# SAMA7G54D2G device description
Architecture: CORTEX-A7; Family: SAMA; Series: SAMA7G
Registers are 32-bit, read-write, reset 0x0 unless marked. A register's access mark holds for its fields unless they carry their own. Offsets are from the block's base; [hi:lo] are bit positions; {n}, {i} and the like mark numbered series; 'fields as' and 'values as' point back to an identical list.

## PMC — Power Management Controller
Instances: PMC 0xE0018000
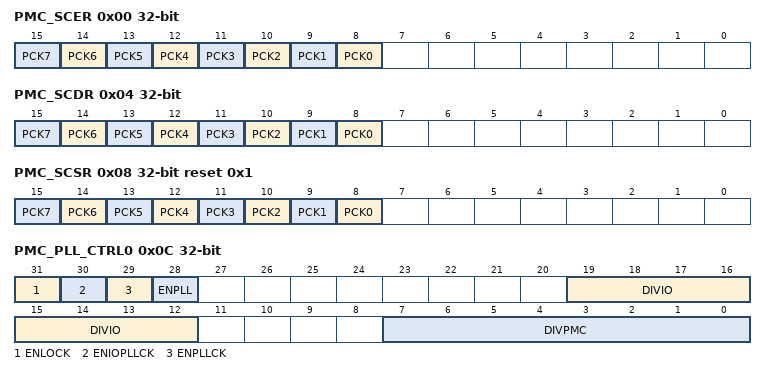
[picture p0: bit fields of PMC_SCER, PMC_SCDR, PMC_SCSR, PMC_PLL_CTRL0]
0x00 PMC_SCER wo reset not defined — System Clock Enable Register
  [all] fields
    0=No effect; 1=Enables the corresponding Programmable Clock output
  [n+8] PCK{n} (n=0..7) — Programmable Clock {n} Output Enable
0x04 PMC_SCDR wo reset not defined (atomic clear of PMC_SCSR) — System Clock Disable Register
  [all] fields
    0=No effect; 1=Disables the corresponding Programmable Clock output
  [n+8] PCK{n} (n=0..7) — Programmable Clock {n} Output Disable
0x08 PMC_SCSR ro reset 0x1 — System Clock Status Register
  [all] fields
    0=The corresponding Programmable Clock output is disabled; 1=The corresponding Programmable Clock output is enabled
  [n+8] PCK{n} (n=0..7) — Programmable Clock {n} Output Status
0x0C PMC_PLL_CTRL0 — PLL Control Register 0
  [31] ENLOCK — Enable PLL Lock
    0=The lock signal sent by the PLL is ignored. The PLL is considered as locked once the start-up time defined by PMC_PLL_UPDT.STUPTIM has elapsed.; 1=The PLL is considered as locked once the start-up time defined by PMC_PLL_UPDT.STUPTIM has elapsed and the lock signal sent by the PLL has risen
  [30] ENIOPLLCK — Enable PLL Clock for IO
    0=The clock generated by the PLL is not send to the IO; 1=The clock generated by the PLL is sent to the IO
  [29] ENPLLCK — Enable PLL Clock for PMC
    0=The clock generated by the PLL is not send to the IP_Acronym; 1=The clock generated by the PLL is sent to the IP_Acronym
  [28] ENPLL — Enable PLL
    0=The PLL is off; 1=The PLL is on
  [19:12] DIVIO — Divider for PAD
  [7:0] DIVPMC — Divider for PMC
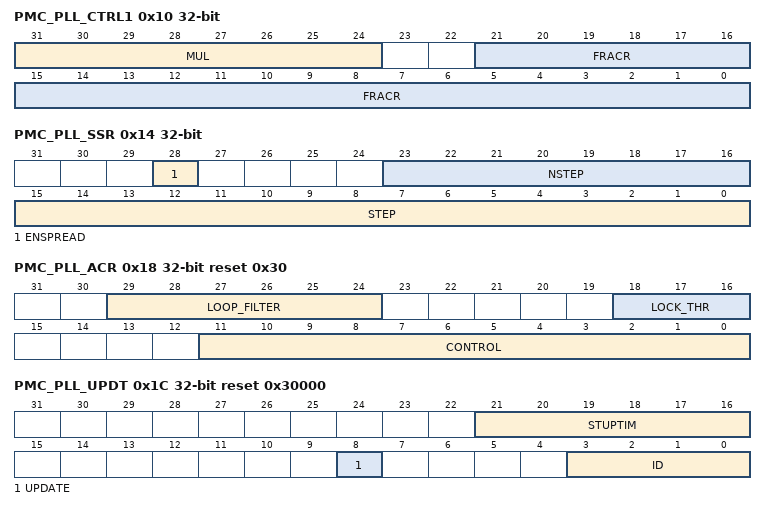
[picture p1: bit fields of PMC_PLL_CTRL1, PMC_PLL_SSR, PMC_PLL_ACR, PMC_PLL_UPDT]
0x10 PMC_PLL_CTRL1 — PLL Control Register 1
  [31:24] MUL — Multiplier Factor Value
  [21:0] FRACR — Fractional Loop Divider Setting
0x14 PMC_PLL_SSR — PLL Spread Spectrum Register
  [28] ENSPREAD — Spread Spectrum Enable
    0=The spread spectrum is not applied to the PLL; 1=The spread spectrum is applied to the PLL
  [23:16] NSTEP — Spread Spectrum Number of Steps
  [15:0] STEP — Spread Spectrum Step Size
0x18 PMC_PLL_ACR reset 0x30 — PLL Analog Control Register
  [29:24] LOOP_FILTER — LOOP Filter Selection
  [18:16] LOCK_THR — PLL Lock Threshold Value Selection
  [11:0] CONTROL — PLL CONTROL Value Selection
0x1C PMC_PLL_UPDT reset 0x30000 — PLL Update Register
  [21:16] STUPTIM — Start-up Time
    0=Only the lock of the PLL is considered to know the lock status of the PLL. If the lock of the PLL is not enabled, the lock never rises.
  [8] UPDATE — PLL Setting Update (write-only)
    0=No effect; 1=The PLL configuration written in PMC_PLL_CTRL0 and PMC_PLL_CTRL1 are applied to the PLL defined by the last ID written in the PMC_PLL_CTRL0 register
  [3:0] ID — PLL ID
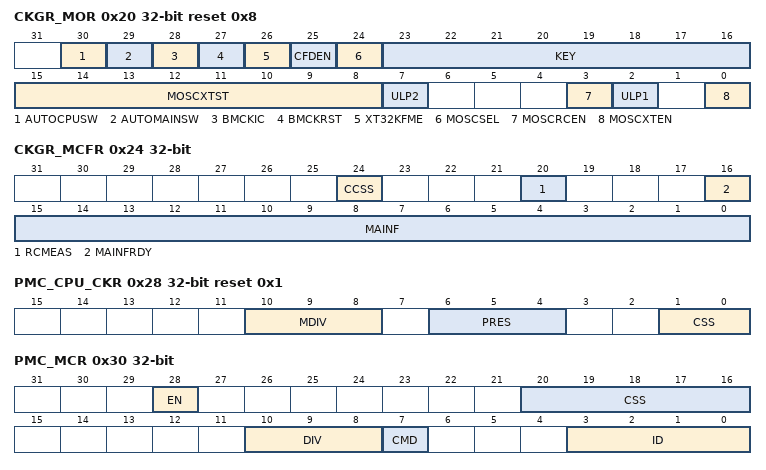
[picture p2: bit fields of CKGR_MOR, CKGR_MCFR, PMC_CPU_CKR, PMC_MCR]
0x20 CKGR_MOR reset 0x8 — Main Oscillator Register
  [30] AUTOCPUSW — Automatic Processor Clock Source Switching
    0=A main crystal oscillator failure detection has no effect on the processor clock source selection; 1=If a main crystal oscillator failure is detected, the processor clock source selection automatically switches to the main clock
  [29] AUTOMAINSW — Automatic Main Clock Source Switching
    0=A main crystal oscillator failure detection has no effect on the main clock source selection; 1=If a main crystal oscillator failure is detected, the main clock source selection automatically switches to the main RC
  [28] BMCKIC — Bad MCK0 Clock Interrupt
    0=An MCK0 clock failure has no effect on the Interrupt Controller; 1=An MCK0 clock failure detection sends an interrupt signal to the Interrupt Controller
  [27] BMCKRST — Bad MCK0 Clock Reset Enable
    0=An MCK0 clock failure detection cannot reset the system; 1=An MCK0 clock failure detection can reset the system if the reset controller is configured accordingly
  [26] XT32KFME — 32.768 kHz Crystal Oscillator Frequency Monitoring Enable
    0=The 32.768 kHz crystal oscillator frequency monitoring is disabled; 1=The 32.768 kHz crystal oscillator frequency monitoring is enabled
  [25] CFDEN — Clock Failure Detector Enable
    0=The clock failure detector is disabled; 1=The clock failure detector is enabled
  [24] MOSCSEL — Main Clock Oscillator Selection
    0=RC (The main RC oscillator is selected.); 1=XT (The main crystal oscillator is selected.)
  [23:16] KEY — Write Access Password
    55=PASSWD (Writing any other value in this field aborts the write operation. Always reads as 0.)
  [15:8] MOSCXTST — Main Crystal Oscillator Start-up Time
  [7] ULP2 — ULP Mode 2 Command (write-only)
    0=No effect; 1=Enables the device to enter ULP mode 2. ULP mode 2 is entered when the processor WFE instruction is executed.
  [3] MOSCRCEN — Main RC Oscillator Enable
    0=The main RC oscillator is disabled; 1=The main RC oscillator is enabled
  [2] ULP1 — ULP Mode 1 Command (write-only)
    0=No effect; 1=Puts the device in ULP mode 1
  [0] MOSCXTEN — Main Crystal Oscillator Enable
    0=The main crystal oscillator is disabled; 1=The main crystal oscillator is enabled or in bypass
0x24 CKGR_MCFR — Main Clock Frequency Register
  [24] CCSS — Counter Clock Source Selection
    0=The measured clock of the MAINF counter is the main RC oscillator; 1=The measured clock of the MAINF counter is the main crystal oscillator
  [20] RCMEAS — RC Oscillator Frequency Measure (write-only)
    0=No effect; 1=Restarts measuring of the frequency of MAINCK. MAINF carries the new frequency as soon as a low-to-high transition occurs on the MAINFRDY flag.
  [16] MAINFRDY — Main Clock Frequency Measure Ready
    0=MAINF value is not valid or the measured oscillator is disabled or a measure has just been started by means of RCMEAS; 1=The measured oscillator has been enabled previously and MAINF value is available
  [15:0] MAINF — Main Clock Frequency
0x28 PMC_CPU_CKR reset 0x1 — CPU Clock Register
  [10:8] MDIV — MCK0 Division
    0=EQ_PCK (MCK0 is FCLK divided by 1.); 1=PCK_DIV2 (MCK0 is FCLK divided by 2.); 2=PCK_DIV4 (MCK0 is FCLK divided by 4.); 3=PCK_DIV3 (MCK0 is FCLK divided by 3.); 4=PCK_DIV5 (MCK0 is FCLK divided by 5.)
  [6:4] PRES — Processor Clock Prescaler
    0=CLK_1 (Selected clock); 1=CLK_2 (Selected clock divided by 2); 2=CLK_4 (Selected clock divided by 4); 3=CLK_8 (Selected clock divided by 8); 4=CLK_16 (Selected clock divided by 16); 5=CLK_32 (Selected clock divided by 32); 6=CLK_64 (Selected clock divided by 64); 7=CLK_3 (Selected clock divided by 3)
  [1:0] CSS — MCK0 Source Selection
    0=SLOW_CLK (MD_SLCK is selected); 1=MAIN_CLK (MAINCK is selected); 2=CPUPLLCK (CPUPLLCK is selected); 3=SYSPLLCK (SYSPLLCK is selected)
0x2C PMC_CPU_RATIO reset 0xF — CPU Clock Ratio Register
  [3:0] RATIO — CPU Clock Ratio
0x30 PMC_MCR — Master Clock Register
  [28] EN — Master Clock Enable
    0=The corresponding MCKx is disabled; 1=The corresponding MCKx is enabled
  [20:16] CSS — Clock Source Selection
    0=MD_SLOW_CLK (MD_SLCK is selected); 1=TD_SLOW_CLOCK (TD_SLCK is selected); 2=MAINCK (MAINCK is selected); 3=MCK0 (MCK0 is selected); 5=SYSPLL (SYSPLL is selected); 6=DDRPLL (DDRPLL is selected); 7=IMGPLL (IMGPLL is selected); 8=BAUDPLL (BAUDPLL is selected); 9=AUDIOPLL (AUDIOPLL is selected); 10=ETHPLL (ETHPLL is selected)
  [10:8] DIV — Divisor Value
    0=MASTER_DIV1 (Selected clock divided by 1); 1=MASTER_DIV2 (Selected clock divided by 2); 2=MASTER_DIV4 (Selected clock divided by 4); 3=MASTER_DIV8 (Selected clock divided by 8); 4=MASTER_DIV16 (Selected clock divided by 16); 5=MASTER_DIV32 (Selected clock divided by 32); 6=MASTER_DIV64 (Selected clock divided by 64); 7=MASTER_DIV3 (Selected clock divided by 3)
  [7] CMD — Command
    0=Read mode; 1=Write mode
  [3:0] ID — Master Clock Index
0x34 PMC_XTALF reset 0x7 — Main XTAL Frequency Register
  [2:0] XTALF — Crystal Frequency
    0=F16M (The main crystal frequency is 16 MHz.); 2=F20M (The main crystal frequency is 20 MHz.); 3=F24M (The main crystal frequency is 24 MHz.); 5=F32M (The main crystal frequency is 32 MHz.)
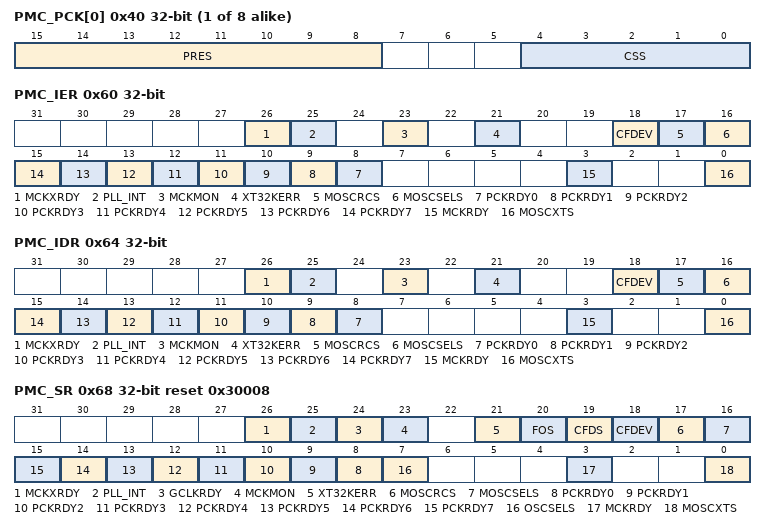
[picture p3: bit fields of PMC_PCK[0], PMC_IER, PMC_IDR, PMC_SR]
{0x40+4i} PMC_PCK[{i}] (i=0..7) — Programmable Clock Register x
  [15:8] PRES — Programmable Clock Prescaler
  [4:0] CSS — Programmable Clock Source Selection
    0=MD_SLOW_CLK (MD_SLCK is selected); 1=TD_SLOW_CLOCK (TD_SLCK is selected); 2=MAINCK (MAINCK is selected); 3=MCK0 (MCK0 is selected); 5=SYSPLL (SYSPLL is selected.); 6=DDRPLL (DDRPLL is selected.); 7=IMGPLL (IMGPLL is selected.); 8=BAUDPLL (BAUDPLL is selected.); 9=AUDIOPLL (AUDIOPLL is selected.); 10=ETHPLL (ETHPLL is selected.)
0x60 PMC_IER wo reset not defined (atomic set of PMC_IMR) — Interrupt Enable Register
  [26] MCKXRDY — Master Clock x [x=1..4] Ready Interrupt Enable
  [25] PLL_INT — PLL Interrupt Enable
  [23] MCKMON — Master Clock 0 Clock Monitor Interrupt Enable
  [21] XT32KERR — 32.768 kHz Crystal Oscillator Error Interrupt Enable
  [18] CFDEV — Clock Failure Detector Event Interrupt Enable
  [17] MOSCRCS — Main RC Oscillator Status Interrupt Enable
  [16] MOSCSELS — Main Clock Source Oscillator Selection Status Interrupt Enable
  [n+8] PCKRDY{n} (n=0..7) — Programmable Clock Ready {n} Interrupt Enable
  [3] MCKRDY — Master Clock 0 Ready Interrupt Enable
  [0] MOSCXTS — Main Crystal Oscillator Status Interrupt Enable
0x64 PMC_IDR wo reset not defined (atomic clear of PMC_IMR) — Interrupt Disable Register
  [26] MCKXRDY — Master Clock x [x=1..4] Ready Interrupt Enable
  [25] PLL_INT — PLL Interrupt Disable
  [23] MCKMON — Master Clock 0 Clock Monitor Interrupt Disable
  [21] XT32KERR — 32.768 kHz Crystal Oscillator Error Interrupt Disable
  [18] CFDEV — Clock Failure Detector Event Interrupt Disable
  [17] MOSCRCS — Main RC Status Interrupt Disable
  [16] MOSCSELS — Main Clock Source Oscillator Selection Status Interrupt Disable
  [n+8] PCKRDY{n} (n=0..7) — Programmable Clock Ready {n} Interrupt Disable
  [3] MCKRDY — Master Clock 0 Ready Interrupt Disable
  [0] MOSCXTS — Main Crystal Oscillator Status Interrupt Disable
0x68 PMC_SR ro reset 0x30008 — Status Register
  [26] MCKXRDY — Master Clock x [x=1..4] Ready Status
    0=At least one Master Clock is not established; 1=AlL Master Clocks are established
  [25] PLL_INT — PLL Interrupt Status
    0=No PLL interrupt has occurred; 1=A PLL interrupt has occurred. PLL interrupt is defined by the configuration of the PMC_IMR register.
  [24] GCLKRDY — GCLK Ready
    0=A GCLK is not ready to use (clock switching in progress); 1=All GCLKs are switched to their selected source clock and ready to use
  [23] MCKMON — Master Clock 0 Clock Monitor Error
    0=The Master Clock 0 is correct or the CPU clock monitor is disabled; 1=The Master Clock 0 is incorrect or has been incorrect for an elapsed period of time since the monitoring has been enabled
  [21] XT32KERR — Slow Crystal Oscillator Error
    0=The frequency of the 32.768 kHz crystal oscillator is correct (32.768 kHz \xb1 1%) or the monitoring is disabled; 1=The frequency of the 32.768 kHz crystal oscillator is incorrect or has been incorrect for an elapsed period of time since the monitoring has been enabled
  [20] FOS — Clock Failure Detector Fault Output Status
    0=The fault output of the clock failure detector is inactive; 1=The fault output of the clock failure detector is active. This status is cleared by writing a '1' to FOCLR in PMC_FOCR.
  [19] CFDS — Clock Failure Detector Status
    0=A clock failure of the main crystal oscillator clock is not detected; 1=A clock failure of the main crystal oscillator clock is detected
  [18] CFDEV — Clock Failure Detector Event
    0=No clock failure detection of the main crystal oscillator clock has occurred since the last read of PMC_SR; 1=At least one clock failure detection of the main crystal oscillator clock has occurred since the last read of PMC_SR
  [17] MOSCRCS — Main RC Oscillator Status
    0=Main RC oscillator is not stabilized; 1=Main RC oscillator is stabilized
  [16] MOSCSELS — Main Clock Source Oscillator Selection Status
    0=Selection is in progress; 1=Selection is done
  [n+8] PCKRDY{n} (n=0..7) — Programmable Clock Ready Status
    0=Programmable Clock x is not ready; 1=Programmable Clock x is ready
  [7] OSCSELS — Timing Domain Slow Clock Oscillator Selection
    0=Embedded slow RC oscillator is selected; 1=32.768 kHz crystal oscillator is selected
  [3] MCKRDY — Master Clock 0 Status
    0=Master Clock 0 is not ready; 1=Master Clock 0 is ready
  [0] MOSCXTS — Main Crystal Oscillator Status
    0=Main crystal oscillator is not stabilized; 1=Main crystal oscillator is stabilized
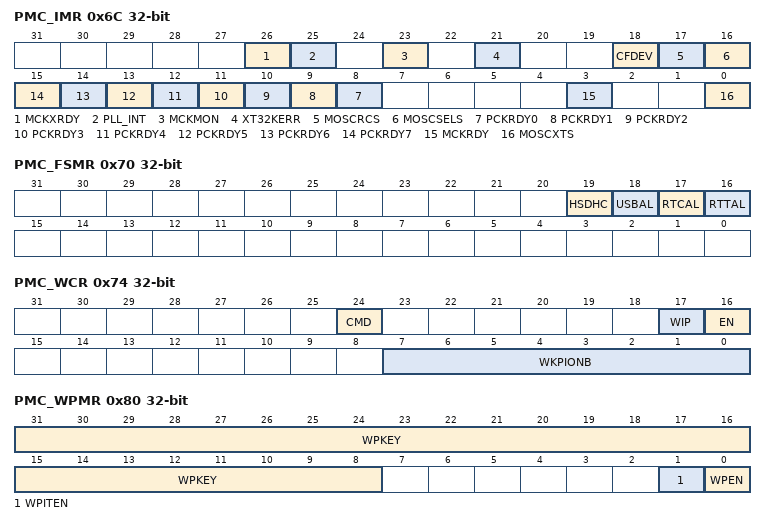
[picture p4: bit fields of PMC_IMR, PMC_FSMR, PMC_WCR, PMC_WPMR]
0x6C PMC_IMR ro — Interrupt Mask Register
  [26] MCKXRDY — Master Clock x [x=1..4] Ready Interrupt Mask
  [25] PLL_INT — PLL Interrupt Mask
  [23] MCKMON — Master Clock 0 Monitor Error Interrupt Mask
  [21] XT32KERR — 32.768 kHz Crystal Oscillator Error Interrupt Mask
  [18] CFDEV — Clock Failure Detector Event Interrupt Mask
  [17] MOSCRCS — Main RC Status Interrupt Mask
  [16] MOSCSELS — Main Clock Source Oscillator Selection Status Interrupt Mask
  [n+8] PCKRDY{n} (n=0..7) — Programmable Clock Ready {n} Interrupt Mask
  [3] MCKRDY — Master Clock 0 Ready Interrupt Mask
  [0] MOSCXTS — Main Crystal Oscillator Status Interrupt Mask
0x70 PMC_FSMR — Fast Startup Mode Register
  [19] HSDHC — HSDHC Alarm
    0=The HSDHC alarm has no effect on the PMC; 1=The HSDHC alarm enables a fast restart signal to the PMC
  [18] USBAL — USB Alarm Enable
    0=The USB alarm has no effect on the IP_Acronym; 1=The USB alarm enables a fast restart signal to the IP_Acronym
  [17] RTCAL — RTC Alarm Enable
    0=The RTC alarm has no effect on the IP_Acronym; 1=The RTC alarm enables a fast restart signal to the IP_Acronym
  [16] RTTAL — RTT Alarm Enable
    0=The RTT alarm has no effect on the IP_Acronym; 1=The RTT alarm enables a fast restart signal to the IP_Acronym
0x74 PMC_WCR — Wakeup Control Register
  [24] CMD — Command
    0=Read mode; 1=Write mode
  [17] WIP — Wakeup Input Polarity
  [16] EN — Wakeup Input Enable
    0=The selected wakeup input has no effect on the IP_Acronym; 1=The selected wakeup input enables a fast restart signal to the IP_Acronym
  [7:0] WKPIONB — Wakeup Input Number
0x78 PMC_FOCR wo reset not defined — Fault Output Clear Register
  [0] FOCLR — Fault Output Clear
0x80 PMC_WPMR — Write Protection Mode Register
  [31:8] WPKEY — Write Protection Key
    0x504D43=PASSWD (Writing any other value in this field aborts the write operation of the WPEN bit. Always reads as 0.)
  [1] WPITEN — Write Protection Interrupt Enable
    0=Disables the write protection on interrupt registers if WPKEY corresponds to 0x504D43 ("PMC" in ASCII); 1=Enables the write protection on interrupt registers if WPKEY corresponds to 0x504D43 ("PMC" in ASCII)
  [0] WPEN — Write Protection Enable
    0=Disables the write protection if WPKEY corresponds to 0x504D43 ("PMC" in ASCII); 1=Enables the write protection if WPKEY corresponds to 0x504D43 ("PMC" in ASCII)
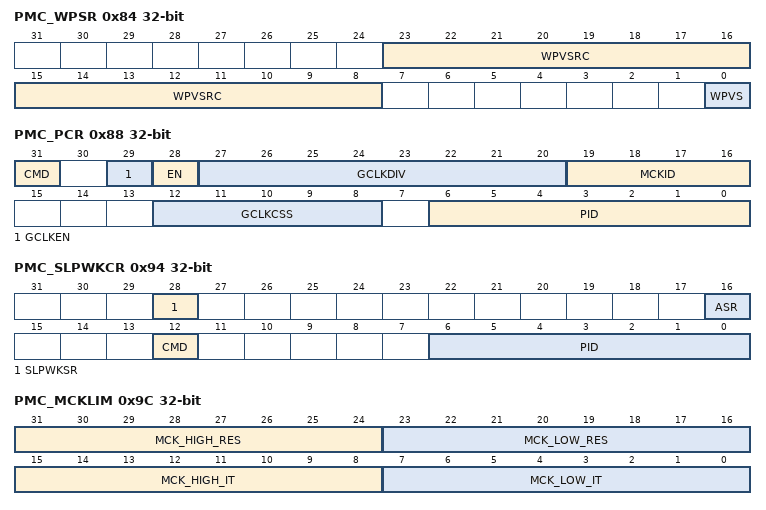
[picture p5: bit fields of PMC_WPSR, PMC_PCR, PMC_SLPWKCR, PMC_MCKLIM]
0x84 PMC_WPSR ro — Write Protection Status Register
  [23:8] WPVSRC — Write Protection Violation Source
  [0] WPVS — Write Protection Violation Status
    0=No write protection violation has occurred since the last read of the PMC_WPSR; 1=A write protection violation has occurred since the last read of the PMC_WPSR. If this violation is an unauthorized attempt to write a protected register, the associated violation is reported into field WPVSRC.
0x88 PMC_PCR — Peripheral Control Register
  [31] CMD — Command
    0=Read mode; 1=Write mode
  [29] GCLKEN — Generic Clock Enable
    0=The selected generic clock is disabled; 1=The selected generic clock is enabled
  [28] EN — Enable
    0=Selected Peripheral clock is disabled; 1=Selected Peripheral clock is enabled
  [27:20] GCLKDIV — Generic Clock Division Ratio
  [19:16] MCKID — Master Clock Index (Read-only)
  [12:8] GCLKCSS — Generic Clock Source Selection
    values as PMC_PCK[0].CSS
  [6:0] PID — Peripheral ID
0x90 PMC_SLPWK_AIPR ro reset not defined — SleepWalking Activity In Progress Register
  [0] AIP — Activity In Progress
    0=There is no activity on peripherals. The asynchronous partial wakeup (SleepWalking) function can be activated on one or more peripherals. The device can enter ULP mode 1 or 2.; 1=One or more peripherals are currently active. The device must not enter ULP mode 1 or 2 if the asynchronous partial wakeup is enabled for one of the following PIDs: FLEXCOMx, and ADCC.
0x94 PMC_SLPWKCR — SleepWalking Control Register
  [28] SLPWKSR — SleepWalking Sleep Register
    0=The asynchronous partial wakeup (SleepWalking) function of the peripheral is disabled; 1=The asynchronous partial wakeup (SleepWalking) function of the peripheral is enabled
  [16] ASR — Activity Status Register
    0=The peripheral x is not currently active; the asynchronous partial wakeup (SleepWalking) function can be activated; 1=The peripheral x is currently active; the asynchronous partial wakeup (SleepWalking) function must not be activated
  [12] CMD — Command
    0=Read mode; 1=Write mode
  [6:0] PID — Peripheral ID
0x9C PMC_MCKLIM — MCK0 Monitor Limits Register
  [31:24] MCK_HIGH_RES — MCK0 Monitoring High Reset Limit
  [23:16] MCK_LOW_RES — MCK0 Monitoring Low RESET Limit
  [15:8] MCK_HIGH_IT — MCK0 Monitoring High IT Limit
  [7:0] MCK_LOW_IT — MCK0 Monitoring Low IT Limit
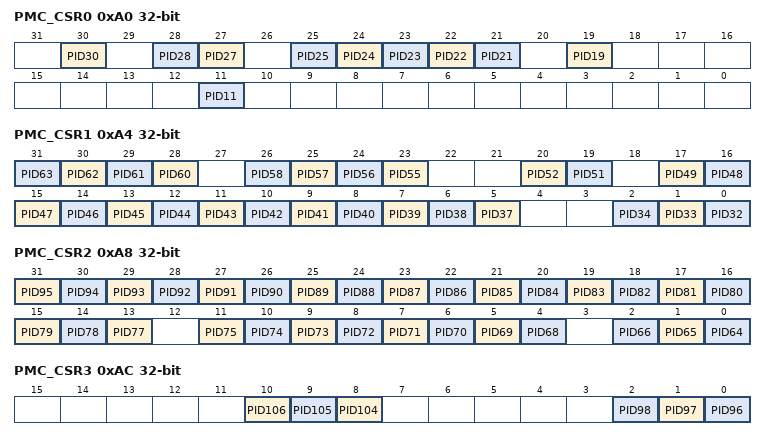
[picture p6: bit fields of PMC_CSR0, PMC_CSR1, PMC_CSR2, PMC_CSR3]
0xA0 PMC_CSR0 ro — Peripheral Clock Status Register 0
  [all] fields
    0=The corresponding peripheral clock is disabled; 1=The corresponding peripheral clock is enabled
  [30] PID30 — Peripheral Clock 30 Status
  [28] PID28 — Peripheral Clock 28 Status
  [27] PID27 — Peripheral Clock 27 Status
  [n] PID{n} (n=21..25) — Peripheral Clock {n} Status
  [19] PID19 — Peripheral Clock 19 Status
  [11] PID11 — Peripheral Clock 11 Status
0xA4 PMC_CSR1 ro — Peripheral Clock Status Register 1
  [all] fields
    values as the fields of PMC_CSR0
  [n-32] PID{n} (n=60..63) — Peripheral Clock {n} Status
  [n-32] PID{n} (n=55..58) — Peripheral Clock {n} Status
  [20] PID52 — Peripheral Clock 52 Status
  [19] PID51 — Peripheral Clock 51 Status
  [n-32] PID{n} (n=37..49) — Peripheral Clock {n} Status
  [2] PID34 — Peripheral Clock 34 Status
  [1] PID33 — Peripheral Clock 33 Status
  [0] PID32 — Peripheral Clock 32 Status
0xA8 PMC_CSR2 ro — Peripheral Clock Status Register 2
  [all] fields
    values as the fields of PMC_CSR0
  [n-64] PID{n} (n=77..95) — Peripheral Clock {n} Status
  [n-64] PID{n} (n=68..75) — Peripheral Clock {n} Status
  [2] PID66 — Peripheral Clock 66 Status
  [1] PID65 — Peripheral Clock 65 Status
  [0] PID64 — Peripheral Clock 64 Status
0xAC PMC_CSR3 ro — Peripheral Clock Status Register 3
  [all] fields
    values as the fields of PMC_CSR0
  [10] PID106 — Peripheral Clock 106 Status
  [9] PID105 — Peripheral Clock 105 Status
  [8] PID104 — Peripheral Clock 104 Status
  [2] PID98 — Peripheral Clock 98 Status
  [1] PID97 — Peripheral Clock 97 Status
  [0] PID96 — Peripheral Clock 96 Status
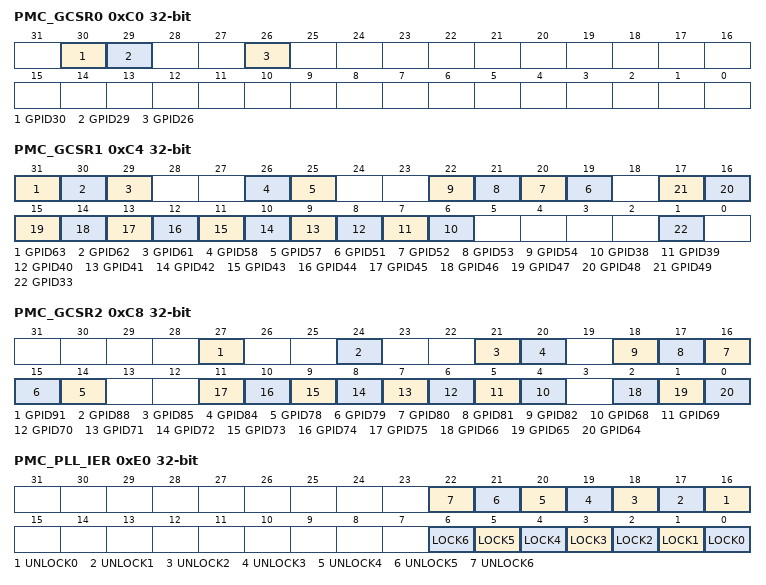
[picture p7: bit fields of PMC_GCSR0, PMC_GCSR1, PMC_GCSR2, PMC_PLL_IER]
0xC0 PMC_GCSR0 ro — Generic Clock Status Register 0
  [all] fields
    0=The corresponding Generic clock is disabled; 1=The corresponding Generic clock is enabled
  [30] GPID30 — Generic Clock 30 Status
  [29] GPID29 — Generic Clock 29 Status
  [26] GPID26 — Generic Clock 26 Status
0xC4 PMC_GCSR1 ro — Generic Clock Status Register 1
  [all] fields
    values as the fields of PMC_GCSR0
  [31] GPID63 — Generic Clock 63 Status
  [30] GPID62 — Generic Clock 62 Status
  [29] GPID61 — Generic Clock 61 Status
  [26] GPID58 — Generic Clock 58 Status
  [25] GPID57 — Generic Clock 57 Status
  [n-32] GPID{n} (n=51..54) — Generic Clock {n} Status
  [n-32] GPID{n} (n=38..49) — Generic Clock {n} Status
  [1] GPID33 — Generic Clock 33 Status
0xC8 PMC_GCSR2 ro — Generic Clock Status Register 2
  [all] fields
    values as the fields of PMC_GCSR0
  [27] GPID91 — Generic Clock 91 Status
  [24] GPID88 — Generic Clock 88 Status
  [21] GPID85 — Generic Clock 85 Status
  [20] GPID84 — Generic Clock 84 Status
  [n-64] GPID{n} (n=78..82) — Generic Clock {n} Status
  [n-64] GPID{n} (n=68..75) — Generic Clock {n} Status
  [2] GPID66 — Generic Clock 66 Status
  [1] GPID65 — Generic Clock 65 Status
  [0] GPID64 — Generic Clock 64 Status
0xCC PMC_GCSR3 ro — Generic Clock Status Register 3
0xE0 PMC_PLL_IER wo reset not defined (atomic set of PMC_PLL_IMR) — PLL Interrupt Enable Register
  [n+16] UNLOCK{n} (n=0..6) — PLL of Index {n} Unlock Interrupt Enable
  [n] LOCK{n} (n=0..6) — PLL of Index {n} Lock Interrupt Enable
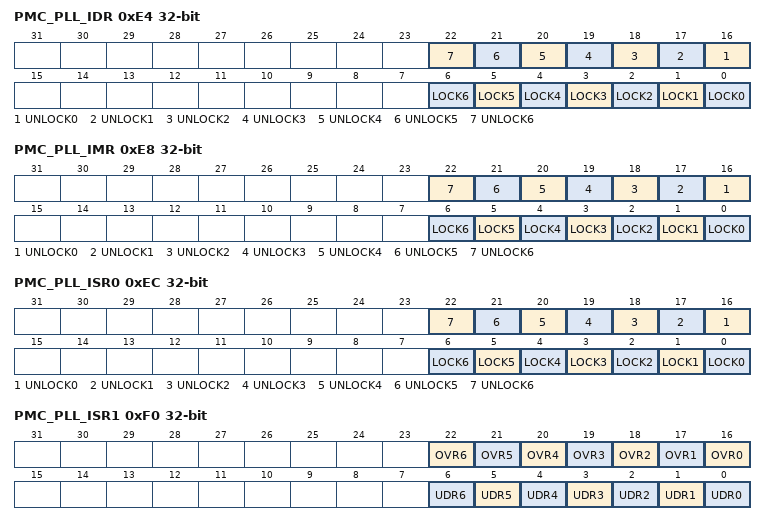
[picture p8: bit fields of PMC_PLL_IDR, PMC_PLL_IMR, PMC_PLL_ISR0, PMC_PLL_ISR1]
0xE4 PMC_PLL_IDR wo reset not defined (atomic clear of PMC_PLL_IMR) — PLL Interrupt Disable Register
  [n+16] UNLOCK{n} (n=0..6) — PLL of Index {n} Unlock Interrupt Disable
  [n] LOCK{n} (n=0..6) — PLL of Index {n} Lock Interrupt Disable
0xE8 PMC_PLL_IMR ro — PLL Interrupt Mask Register
  [n+16] UNLOCK{n} (n=0..6) — PLL of Index {n} Unlock Interrupt Mask
  [n] LOCK{n} (n=0..6) — PLL of Index {n} Lock Interrupt Mask
0xEC PMC_PLL_ISR0 ro — PLL Interrupt Status Register 0
  [n+16] UNLOCK{n} (n=0..6) — PLL of Index {n} Unlock Interrupt Status
    0=PLL is not unlocked; 1=PLLx is unlocked. To know the unlock type, the PMC_PISR1 register can be read.
  [n] LOCK{n} (n=0..6) — PLL of Index {n} Lock Interrupt Status
    0=PLLx is not locked; 1=PLLx is locked
0xF0 PMC_PLL_ISR1 ro — PLL Interrupt Status Register 1
  [n+16] OVR{n} (n=0..6) — PLLx Overflow
    0=PLL is not in overflow state; 1=PLL encountered an overflow
  [n] UDR{n} (n=0..6) — PLLx Underflow
    0=PLL is not in underflow state; 1=PLL encountered an underflow
